# Template register map
Vendor: VendorName Co.Ltd; Series: SeriesName; File version: 1.2
CPU: CM7 r0p1, little endian, MPU, FPU, 4 interrupt priority bits
Registers are 32-bit, read-write, no defined reset value unless marked. A register's access mark holds for its fields unless they carry their own. Offsets are from the block's base; [hi:lo] are bit positions; lines under a group give offsets from that group; {n}, {i} and the like mark numbered series.

## FMU — Fault Management Unit
Base 0x40099000
0x00 PID ro — FMU module ID register
  [31:0] PID — FMU PID[31:0] bit: product ID
0x04 MODE — FMU work mode select register
  [3:0] MODE — FMU MODE[3:0] bit: FMU work mode select
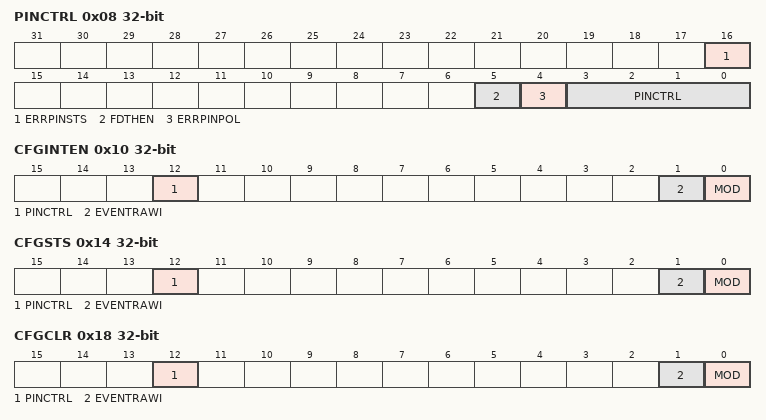
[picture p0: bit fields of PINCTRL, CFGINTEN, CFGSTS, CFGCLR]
0x08 PINCTRL — FMU fault mark pin control register
  [16] ERRPINSTS ro — FMU ERRPINSTS bit: fault mark pin status flag
  [5] FDTHEN — FMU FDTHEN bit: loss of clock marking directly to the function of fault flag pin
  [4] ERRPINPOL — FMU ERRPINPOL bit: fault mark pin polarity control
  [3:0] PINCTRL — FMU PINCTRL[3:0] bit: fault mark pin control
0x0C CNTPRE — FMU counter preload register
  [23:0] COUNT — FMU COUNT[23:0] bit: preload to counter
0x10 CFGINTEN — FMU configuration fault interrupt enable register
  [12] PINCTRL — FMU PINCTRL bit: FMUPINCTRL register fault interrupt enable
  [1] EVENTRAWI — FMU EVENTRAWI bit: initial event of FMU register fault interrupt enable
  [0] MOD — FMU MOD bit: FMUMOD register fault interrupt enable
0x14 CFGSTS ro — FMU configuration fault status register
  [12] PINCTRL — FMU PINCTRL bit: FMUPINCTRL register fault status
  [1] EVENTRAWI — FMU EVENTRAWI bit: initial event of FMU register fault status
  [0] MOD — FMU MOD bit: FMUMOD register fault status
0x18 CFGCLR wo — FMU configuration fault status clear register
  [12] PINCTRL — FMU PINCTRL bit: FMUPINCTRL register fault status clear
  [1] EVENTRAWI — FMU EVENTRAWI bit: initial event of FMU register fault status clear
  [0] MOD — FMU MOD bit: FMUMOD register fault status clear
{0x40+0x2C*i} EVTINTCFG[{i}] (i=0..1) group — Grouping of EVTINTCFG0~EVTINTCFG1
  0x00 EVTSET wo — FMU software force generating event register x
    [31:0] EVTSET — FMU EVTSET[31:0] bit: software force event x
  0x04 EVTSTS ro — FMU event status register x
    [31:0] EVTSTS — FMU EVTSTS[31:0] bit: software read event source x which inputs to FMU
  0x08 EVTCLR wo — FMU event status clear register x
    [31:0] EVTCLR — FMU EVTCLR[31:0] bit: software clear event source x which FMU maintain
  0x14 INTSTS ro — FMU interrupt status register x
    [31:0] INTSTS — FMU INTSTS[31:0] bit: software read FMU interrupt source x
  0x18 INTCLR wo — FMU interrupt status clear register x
    [31:0] INTCLR — FMU INTCLR[31:0] bit: software clear FMU interrupt status x
  0x24 PINSTS ro — FMU fault mark pin status register x
    [31:0] PINSTS — FMU PINSTS[31:0] bit: software read event source x which generates FMU fault mark pin valid
  0x28 PINCLR wo — FMU fault mark pin status clear register x
    [31:0] PINCLR — FMU PINCLR[31:0] bit: software clear event status x which generates FMU fault mark pin valid
  0x30 INTENSET — FMU interrupt enable set register x
    [31:0] INTENSET — FMU INTENSET[31:0] bit: software interrupt enable event x
  0x34 INTENCLR — FMU interrupt enable clear register x
    [31:0] INTENCLR — FMU INTENCLR[31:0] bit: software invalid interrupt enable event x
  0x38 PINENSET — FMU fault mark pin enable set register x
    [31:0] PINENSET — FMU PINENSET[31:0] bit: software enable event x fault mark pin function
  0x3C PINENCLR — FMU fault mark pin enable clear register x
    [31:0] PINENCLR — FMU PINENCLR[31:0] bit: software invalid enable event x fault mark pin function
0x200 SFTRST wo — FMU module software reset register
  [3:0] SFTRST — FMU SFTRST[3:0] bit: FMU module global reset
0x204 LOCK wo — FMU module register write lock register
  [31:0] LOCK — FMU LOCK[31:0] bit: write 0x43533636 to unlock FMU register's writing function
{0x210+4i} EVTCTRL[{i}] (i=0..3) — Grouping of EVTCTRL1~EVTCTRL4
  [31:0] FMUEVTCTRL — FMU FMUEVTCTRL[31:0] bit: event x assign to which CPU
